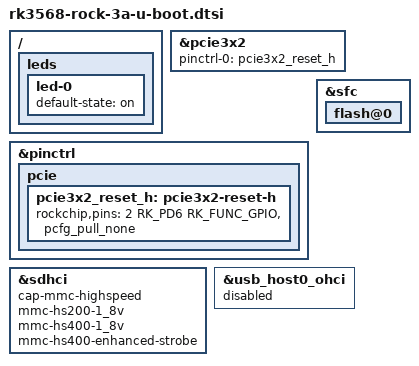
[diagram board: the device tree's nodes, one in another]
// SPDX-License-Identifier: GPL-2.0+
/*
 * (C) Copyright 2021 Rockchip Electronics Co., Ltd
 * (C) Copyright 2023 Akash Gajjar <gajjar04akash@gmail.com>
 */

#include "rk356x-u-boot.dtsi"

/ {
	leds {
		led-0 {
			default-state = "on";
		};
	};
};

&pcie3x2 {
	pinctrl-0 = <&pcie3x2_reset_h>;
};

&pinctrl {
	pcie {
		pcie3x2_reset_h: pcie3x2-reset-h {
			rockchip,pins = <2 RK_PD6 RK_FUNC_GPIO &pcfg_pull_none>;
		};
	};
};

&sdhci {
	cap-mmc-highspeed;
	mmc-hs200-1_8v;
	mmc-hs400-1_8v;
	mmc-hs400-enhanced-strobe;
};

&sfc {
	flash@0 {
		bootph-pre-ram;
		bootph-some-ram;
	};
};

&usb_host0_ohci {
	status = "disabled";
};
